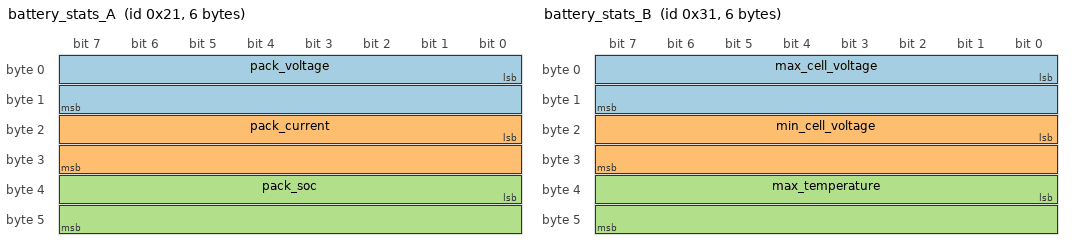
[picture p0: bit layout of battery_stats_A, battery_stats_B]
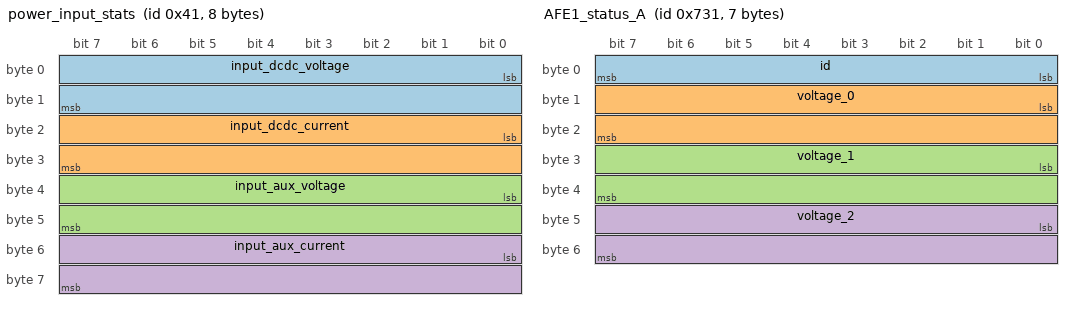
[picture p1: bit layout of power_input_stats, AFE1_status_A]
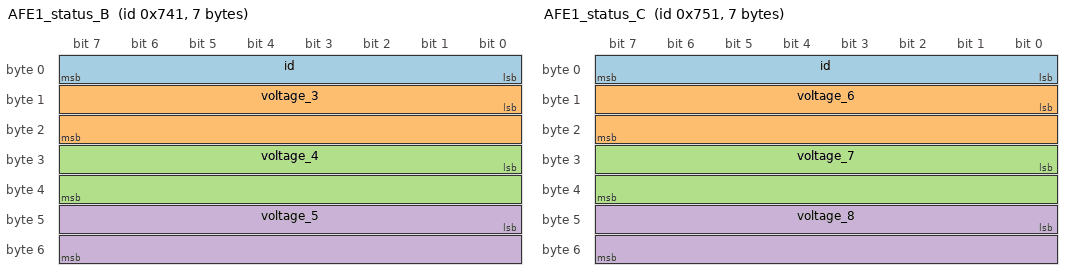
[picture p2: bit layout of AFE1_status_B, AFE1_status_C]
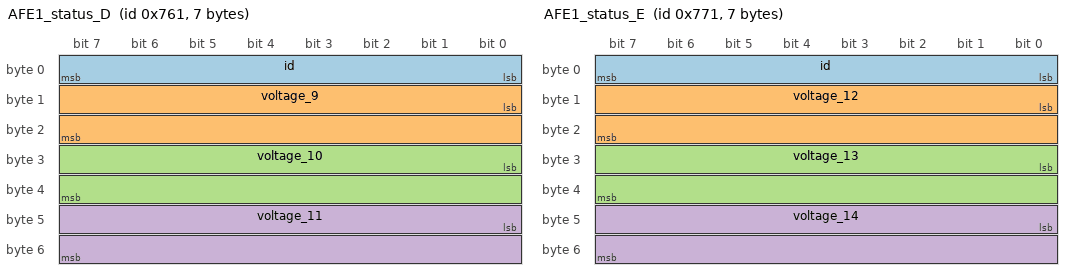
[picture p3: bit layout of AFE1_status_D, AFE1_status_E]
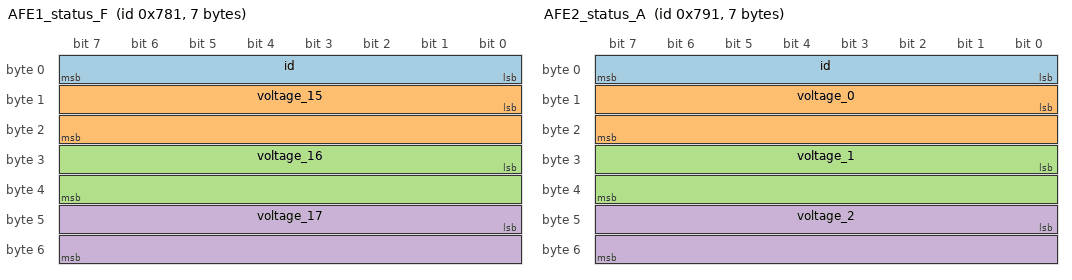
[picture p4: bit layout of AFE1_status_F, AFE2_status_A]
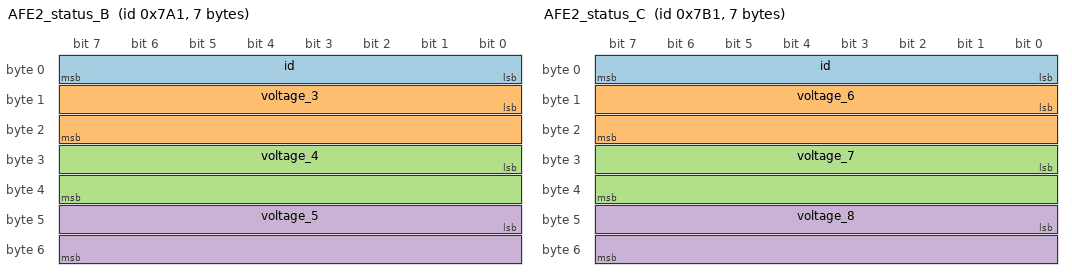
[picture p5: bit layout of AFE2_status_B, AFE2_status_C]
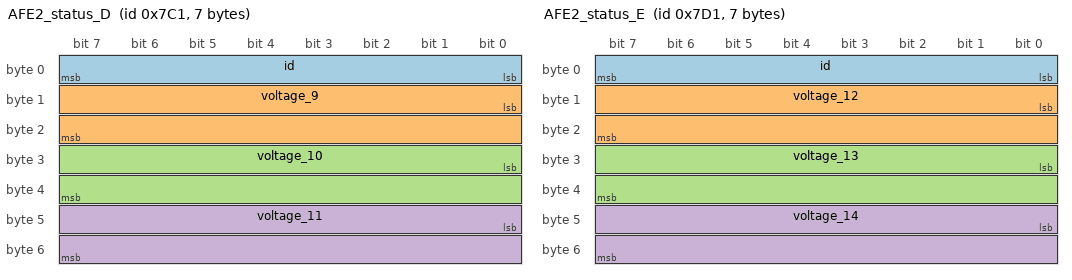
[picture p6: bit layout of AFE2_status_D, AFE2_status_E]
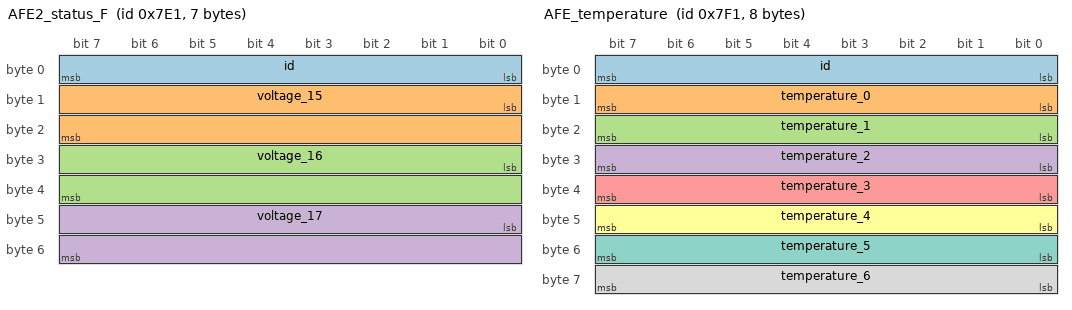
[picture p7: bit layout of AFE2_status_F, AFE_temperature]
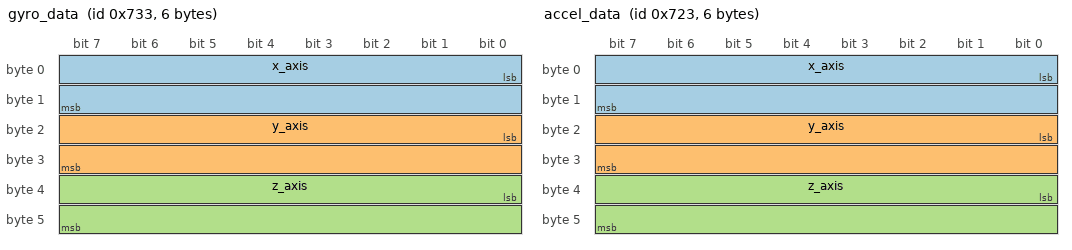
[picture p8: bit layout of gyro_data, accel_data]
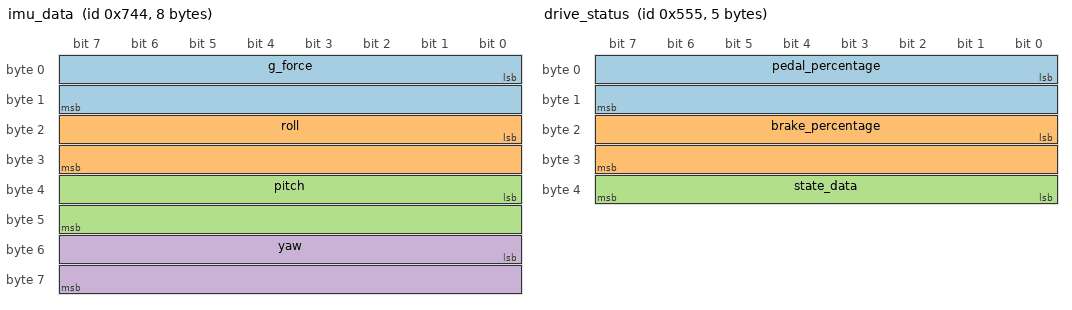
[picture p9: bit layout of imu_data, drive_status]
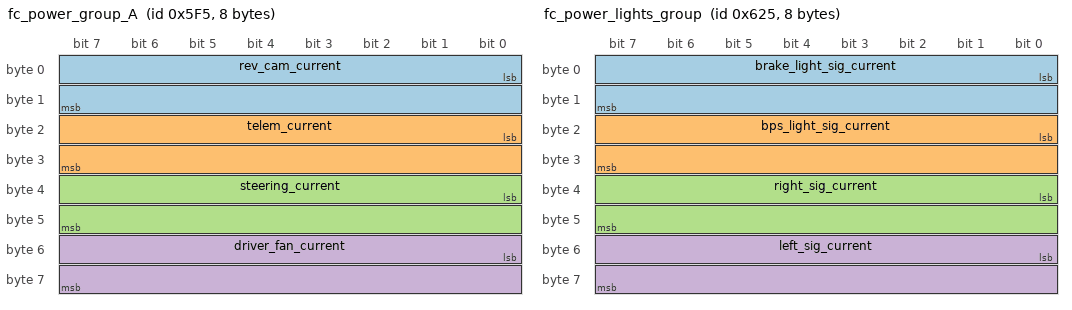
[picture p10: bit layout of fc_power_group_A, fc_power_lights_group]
NS_ :

BS_:

BU_: STEERING REAR_CONTROLLER CAN_COMMUNICATION IMU TELEMETRY FRONT_CONTROLLER

BO_  96  steering: 5 steering
  SG_ cruise_control_target_velocity : 0|32@1+ (1,0) [0|4294967295] "" telemetry, front_controller, rear_controller
  SG_ buttons : 32|8@1+ (1,0) [|] "" telemetry, front_controller, rear_controller

BO_  17  rear_controller_status: 4 rear_controller
  SG_ triggers : 0|32@1+ (1,0) [|] "" telemetry, front_controller, steering

BO_  33  battery_stats_A: 6 rear_controller
  SG_ pack_voltage : 0|16@1+ (1,0) [0|65535] "" telemetry, front_controller, steering
  SG_ pack_current : 16|16@1+ (1,0) [0|65535] "" telemetry, front_controller, steering
  SG_ pack_soc : 32|16@1+ (1,0) [0|65535] "" telemetry, front_controller, steering

BO_  49  battery_stats_B: 6 rear_controller
  SG_ max_cell_voltage : 0|16@1+ (1,0) [0|65535] "" telemetry, front_controller, steering
  SG_ min_cell_voltage : 16|16@1+ (1,0) [0|65535] "" telemetry, front_controller, steering
  SG_ max_temperature : 32|16@1+ (1,0) [0|65535] "" telemetry, front_controller, steering

BO_  65  power_input_stats: 8 rear_controller
  SG_ input_dcdc_voltage : 0|16@1+ (1,0) [0|65535] "" telemetry, steering
  SG_ input_dcdc_current : 16|16@1+ (1,0) [0|65535] "" telemetry, steering
  SG_ input_aux_voltage : 32|16@1+ (1,0) [0|65535] "" telemetry, steering
  SG_ input_aux_current : 48|16@1+ (1,0) [0|65535] "" telemetry, steering

BO_   1825 AFE_discharge_bitset: 8 rear_controller
  SG_ AFE1 : 0|32@1+ (1,0) [|] "" telemetry, steering
  SG_ AFE2 : 32|32@1+ (1,0) [|] "" telemetry, steering

BO_   1841 AFE1_status_A: 7 rear_controller
  SG_ id : 0|8@1+ (1,0) [0|255] "" telemetry, steering
  SG_ voltage_0 : 8|16@1+ (1,0) [0|65535] "" telemetry, steering
  SG_ voltage_1 : 24|16@1+ (1,0) [0|65535] "" telemetry, steering
  SG_ voltage_2 : 40|16@1+ (1,0) [0|65535] "" telemetry, steering

BO_   1857 AFE1_status_B: 7 rear_controller
  SG_ id : 0|8@1+ (1,0) [0|255] "" telemetry, steering
  SG_ voltage_3 : 8|16@1+ (1,0) [0|65535] "" telemetry, steering
  SG_ voltage_4 : 24|16@1+ (1,0) [0|65535] "" telemetry, steering
  SG_ voltage_5 : 40|16@1+ (1,0) [0|65535] "" telemetry, steering

BO_   1873 AFE1_status_C: 7 rear_controller
  SG_ id : 0|8@1+ (1,0) [0|255] "" telemetry, steering
  SG_ voltage_6 : 8|16@1+ (1,0) [0|65535] "" telemetry, steering
  SG_ voltage_7 : 24|16@1+ (1,0) [0|65535] "" telemetry, steering
  SG_ voltage_8 : 40|16@1+ (1,0) [0|65535] "" telemetry, steering

BO_   1889 AFE1_status_D: 7 rear_controller
  SG_ id : 0|8@1+ (1,0) [0|255] "" telemetry, steering
  SG_ voltage_9 : 8|16@1+ (1,0) [0|65535] "" telemetry, steering
  SG_ voltage_10 : 24|16@1+ (1,0) [0|65535] "" telemetry, steering
  SG_ voltage_11 : 40|16@1+ (1,0) [0|65535] "" telemetry, steering

BO_   1905 AFE1_status_E: 7 rear_controller
  SG_ id : 0|8@1+ (1,0) [0|255] "" telemetry, steering
  SG_ voltage_12 : 8|16@1+ (1,0) [0|65535] "" telemetry, steering
  SG_ voltage_13 : 24|16@1+ (1,0) [0|65535] "" telemetry, steering
  SG_ voltage_14 : 40|16@1+ (1,0) [0|65535] "" telemetry, steering

BO_   1921 AFE1_status_F: 7 rear_controller
  SG_ id : 0|8@1+ (1,0) [0|255] "" telemetry, steering
  SG_ voltage_15 : 8|16@1+ (1,0) [0|65535] "" telemetry, steering
  SG_ voltage_16 : 24|16@1+ (1,0) [0|65535] "" telemetry, steering
  SG_ voltage_17 : 40|16@1+ (1,0) [0|65535] "" telemetry, steering

BO_   1937 AFE2_status_A: 7 rear_controller
  SG_ id : 0|8@1+ (1,0) [0|255] "" telemetry, steering
  SG_ voltage_0 : 8|16@1+ (1,0) [0|65535] "" telemetry, steering
  SG_ voltage_1 : 24|16@1+ (1,0) [0|65535] "" telemetry, steering
  SG_ voltage_2 : 40|16@1+ (1,0) [0|65535] "" telemetry, steering

BO_   1953 AFE2_status_B: 7 rear_controller
  SG_ id : 0|8@1+ (1,0) [0|255] "" telemetry, steering
  SG_ voltage_3 : 8|16@1+ (1,0) [0|65535] "" telemetry, steering
  SG_ voltage_4 : 24|16@1+ (1,0) [0|65535] "" telemetry, steering
  SG_ voltage_5 : 40|16@1+ (1,0) [0|65535] "" telemetry, steering

BO_   1969 AFE2_status_C: 7 rear_controller
  SG_ id : 0|8@1+ (1,0) [0|255] "" telemetry, steering
  SG_ voltage_6 : 8|16@1+ (1,0) [0|65535] "" telemetry, steering
  SG_ voltage_7 : 24|16@1+ (1,0) [0|65535] "" telemetry, steering
  SG_ voltage_8 : 40|16@1+ (1,0) [0|65535] "" telemetry, steering

BO_   1985 AFE2_status_D: 7 rear_controller
  SG_ id : 0|8@1+ (1,0) [0|255] "" telemetry, steering
  SG_ voltage_9 : 8|16@1+ (1,0) [0|65535] "" telemetry, steering
  SG_ voltage_10 : 24|16@1+ (1,0) [0|65535] "" telemetry, steering
  SG_ voltage_11 : 40|16@1+ (1,0) [0|65535] "" telemetry, steering

BO_   2001 AFE2_status_E: 7 rear_controller
  SG_ id : 0|8@1+ (1,0) [0|255] "" telemetry, steering
  SG_ voltage_12 : 8|16@1+ (1,0) [0|65535] "" telemetry, steering
  SG_ voltage_13 : 24|16@1+ (1,0) [0|65535] "" telemetry, steering
  SG_ voltage_14 : 40|16@1+ (1,0) [0|65535] "" telemetry, steering

BO_   2017 AFE2_status_F: 7 rear_controller
  SG_ id : 0|8@1+ (1,0) [0|255] "" telemetry, steering
  SG_ voltage_15 : 8|16@1+ (1,0) [0|65535] "" telemetry, steering
  SG_ voltage_16 : 24|16@1+ (1,0) [0|65535] "" telemetry, steering
  SG_ voltage_17 : 40|16@1+ (1,0) [0|65535] "" telemetry, steering

BO_   2033 AFE_temperature: 8 rear_controller
  SG_ id : 0|8@1+ (1,0) [0|255] "" telemetry, steering
  SG_ temperature_0 : 8|8@1+ (1,0) [0|255] "" telemetry, steering
  SG_ temperature_1 : 16|8@1+ (1,0) [0|255] "" telemetry, steering
  SG_ temperature_2 : 24|8@1+ (1,0) [0|255] "" telemetry, steering
  SG_ temperature_3 : 32|8@1+ (1,0) [0|255] "" telemetry, steering
  SG_ temperature_4 : 40|8@1+ (1,0) [0|255] "" telemetry, steering
  SG_ temperature_5 : 48|8@1+ (1,0) [0|255] "" telemetry, steering
  SG_ temperature_6 : 56|8@1+ (1,0) [0|255] "" telemetry, steering

BO_   1906 fast_one_shot_msg: 4 can_communication
  SG_ sig1 : 0|16@1+ (1,0) [0|65535] "" can_communication
  SG_ sig2 : 16|16@1+ (1,0) [0|65535] "" can_communication

BO_   1890 medium_one_shot_msg: 4 can_communication
  SG_ sig1 : 0|16@1+ (1,0) [0|65535] "" can_communication
  SG_ sig2 : 16|16@1+ (1,0) [0|65535] "" can_communication

BO_   1874 slow_one_shot_msg: 4 can_communication
  SG_ sig1 : 0|16@1+ (1,0) [0|65535] "" can_communication
  SG_ sig2 : 16|16@1+ (1,0) [0|65535] "" can_communication

BO_   1843 gyro_data: 6 imu
  SG_ x_axis : 0|16@1+ (1,0) [0|65535] "" telemetry
  SG_ y_axis : 16|16@1+ (1,0) [0|65535] "" telemetry
  SG_ z_axis : 32|16@1+ (1,0) [0|65535] "" telemetry

BO_   1827 accel_data: 6 imu
  SG_ x_axis : 0|16@1+ (1,0) [0|65535] "" telemetry
  SG_ y_axis : 16|16@1+ (1,0) [0|65535] "" telemetry
  SG_ z_axis : 32|16@1+ (1,0) [0|65535] "" telemetry

BO_   1860 imu_data: 8 telemetry
  SG_ g_force : 0|16@1+ (1,0) [0|65535] "" steering
  SG_ roll : 16|16@1+ (1,0) [0|65535] "" steering
  SG_ pitch : 32|16@1+ (1,0) [0|65535] "" steering
  SG_ yaw : 48|16@1+ (1,0) [0|65535] "" steering

BO_   1365 drive_status: 5 front_controller
  SG_ pedal_percentage : 0|16@1+ (1,0) [0|65535] "" telemetry, steering, rear_controller
  SG_ brake_percentage : 16|16@1+ (1,0) [0|65535] "" telemetry, steering, rear_controller
  SG_ state_data : 32|8@1+ (1,0) [|] "" telemetry, steering, rear_controller

BO_   1525 fc_power_group_A: 8 front_controller
  SG_ rev_cam_current : 0|16@1+ (1,0) [0|65535] "" telemetry
  SG_ telem_current : 16|16@1+ (1,0) [0|65535] "" telemetry
  SG_ steering_current : 32|16@1+ (1,0) [0|65535] "" telemetry
  SG_ driver_fan_current : 48|16@1+ (1,0) [0|65535] "" telemetry

BO_   1621 fc_power_group_B: 4 front_controller
  SG_ horn_current : 0|16@1+ (1,0) [0|65535] "" telemetry
  SG_ spare_current : 16|16@1+ (1,0) [0|65535] "" telemetry

BO_   1573 fc_power_lights_group: 8 front_controller
  SG_ brake_light_sig_current : 0|16@1+ (1,0) [0|65535] "" telemetry
  SG_ bps_light_sig_current : 16|16@1+ (1,0) [0|65535] "" telemetry
  SG_ right_sig_current : 32|16@1+ (1,0) [0|65535] "" telemetry
  SG_ left_sig_current : 48|16@1+ (1,0) [0|65535] "" telemetry
